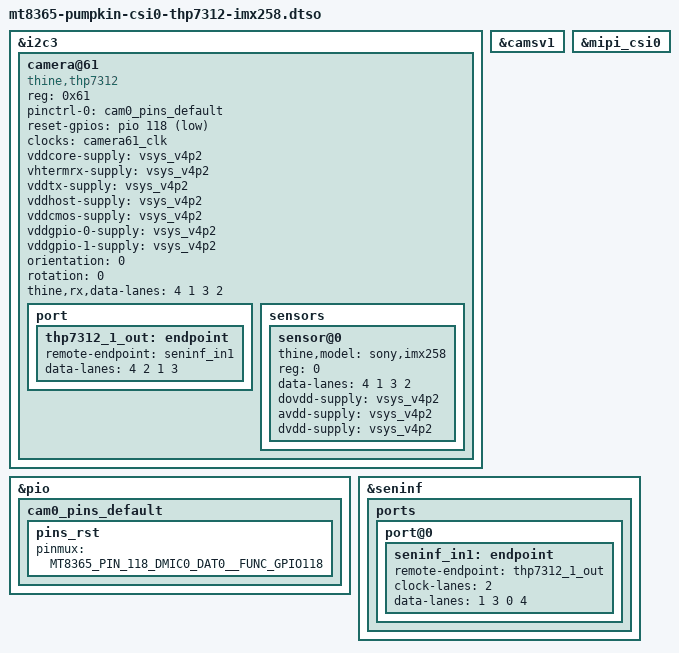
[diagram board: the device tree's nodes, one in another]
// SPDX-License-Identifier: GPL-2.0
/*
 * Copyright (c) 2023 Ideas on Board
 * Author: Paul Elder <paul.elder@ideasonboard.com>
 */

#include <dt-bindings/gpio/gpio.h>
#include <dt-bindings/pinctrl/mt8365-pinfunc.h>

#include "mt8365-pumpkin-common-thp7312.dtsi"

&i2c3 {
	camera@61 {
		compatible = "thine,thp7312";
		reg = <0x61>;

		/* Uncomment and set reg to 0x60 for flash mode. */
		// thine,boot-mode = <0>;

		pinctrl-names = "default";
		pinctrl-0 = <&cam0_pins_default>;

		reset-gpios = <&pio 118 GPIO_ACTIVE_LOW>;
		clocks = <&camera61_clk>;

		vddcore-supply = <&vsys_v4p2>;
		vhtermrx-supply = <&vsys_v4p2>;
		vddtx-supply = <&vsys_v4p2>;
		vddhost-supply = <&vsys_v4p2>;
		vddcmos-supply = <&vsys_v4p2>;
		vddgpio-0-supply = <&vsys_v4p2>;
		vddgpio-1-supply = <&vsys_v4p2>;

		orientation = <0>;
		rotation = <0>;

		thine,rx,data-lanes = <4 1 3 2>;

		port {
			thp7312_1_out: endpoint {
				remote-endpoint = <&seninf_in1>;
				data-lanes = <4 2 1 3>;
			};
		};

		sensors {
			#address-cells = <1>;
			#size-cells = <0>;

			sensor@0 {
				thine,model = "sony,imx258";
				reg = <0>;

				data-lanes = <4 1 3 2>;

				dovdd-supply = <&vsys_v4p2>;
				avdd-supply = <&vsys_v4p2>;
				dvdd-supply = <&vsys_v4p2>;
			};
		};
	};
};

&camsv1 {
	status = "okay";
};

&mipi_csi0 {
	status = "okay";
};

&pio {
	cam0_pins_default: cam0_pins_default {
		pins_rst {
			pinmux = <MT8365_PIN_118_DMIC0_DAT0__FUNC_GPIO118>;
		};
	};
};

&seninf {
	status = "okay";

	ports {
		port@0 {
			seninf_in1: endpoint {
				remote-endpoint = <&thp7312_1_out>;
				clock-lanes = <2>;
				data-lanes = <1 3 0 4>;
			};
		};
	};
};
